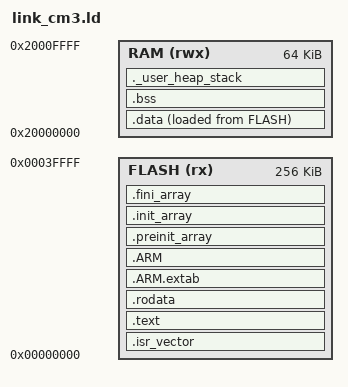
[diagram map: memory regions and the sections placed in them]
/*
 * link_cm3.ld — Linker script for QEMU lm3s6965evb (Cortex-M3)
 * FLASH: 0x00000000, 256KB | RAM: 0x20000000, 64KB
 */
ENTRY(Reset_Handler)

MEMORY {
    FLASH (rx)  : ORIGIN = 0x00000000, LENGTH = 256K
    RAM   (rwx) : ORIGIN = 0x20000000, LENGTH = 64K
}

_estack = ORIGIN(RAM) + LENGTH(RAM);  /* Top of RAM = initial stack pointer */

SECTIONS {

    /* Vector table — must be at address 0 */
    .isr_vector : {
        . = ALIGN(4);
        KEEP(*(.isr_vector))
        . = ALIGN(4);
    } >FLASH

    /* Code and read-only data */
    .text : {
        . = ALIGN(4);
        *(.text)
        *(.text*)
        *(.glue_7)
        *(.glue_7t)
        *(.eh_frame)
        KEEP(*(.init))
        KEEP(*(.fini))
        . = ALIGN(4);
        _etext = .;
    } >FLASH

    /* Read-only data */
    .rodata : {
        . = ALIGN(4);
        *(.rodata)
        *(.rodata*)
        . = ALIGN(4);
    } >FLASH

    /* ARM exception tables */
    .ARM.extab : { *(.ARM.extab* .gnu.linkonce.armextab.*) } >FLASH
    .ARM        : {
        __exidx_start = .;
        *(.ARM.exidx*)
        __exidx_end = .;
    } >FLASH

    /* Preinit / init / fini arrays */
    .preinit_array : {
        PROVIDE_HIDDEN(__preinit_array_start = .);
        KEEP(*(.preinit_array*))
        PROVIDE_HIDDEN(__preinit_array_end = .);
    } >FLASH

    .init_array : {
        PROVIDE_HIDDEN(__init_array_start = .);
        KEEP(*(SORT(.init_array.*)))
        KEEP(*(.init_array*))
        PROVIDE_HIDDEN(__init_array_end = .);
    } >FLASH

    .fini_array : {
        PROVIDE_HIDDEN(__fini_array_start = .);
        KEEP(*(SORT(.fini_array.*)))
        KEEP(*(.fini_array*))
        PROVIDE_HIDDEN(__fini_array_end = .);
    } >FLASH

    /* Initialised data — copied from flash to RAM by startup */
    _sidata = LOADADDR(.data);
    .data : {
        . = ALIGN(4);
        _sdata = .;
        *(.data)
        *(.data*)
        . = ALIGN(4);
        _edata = .;
    } >RAM AT >FLASH

    /* Zero-initialised data */
    .bss : {
        . = ALIGN(4);
        _sbss = .;
        __bss_start__ = .;
        *(.bss)
        *(.bss*)
        *(COMMON)
        . = ALIGN(4);
        _ebss = .;
        __bss_end__ = .;
    } >RAM

    /* Heap and stack in remaining RAM */
    ._user_heap_stack : {
        . = ALIGN(8);
        PROVIDE(end = .);
        PROVIDE(__end__ = .);
        . = . + 0x400;  /* Heap: 1KB */
        . = . + 0x800;  /* Stack: 2KB */
        . = ALIGN(8);
    } >RAM

    /* Discard unused sections */
    /DISCARD/ : {
        libc.a(*)
        libm.a(*)
        libgcc.a(*)
    }
}
